# CC2756 register map
File version: 1.0
CPU: CM4 r0p4, little endian, no MPU, no FPU, VTOR, 3 interrupt priority bits
Registers are 32-bit, read-write, reset 0x0 unless marked. A register's access mark holds for its fields unless they carry their own. Offsets are from the block's base; [hi:lo] are bit positions; lines under a group give offsets from that group; {n}, {i} and the like mark numbered series; 'fields as' and 'values as' point back to an identical list.

## FLASH
Base 0x40021000
0x20 IIDX ro — Interrupt Index Register: The IIDX register provides the highest priority enabled interrupt index. PSD compliant register. Note that it is not recommended to use this register if the system clock is running at a slower clock frequency than the flash wrapper clock. If this is the case, then reading this register may fail to update the RIS register correctly. The MIS register should be read directly, and a write to ICLR should be used to clear interrupts when this clock relationship is present.
  [0] STAT — Indicates which interrupt has fired. 0x0 means no event pending. The priority order is fixed. On each read, only one interrupt is indicated. On a read, the current interrupt (highest priority) is automatically cleared by the hardware and the corresponding interrupt flags in the RIS and MIS are cleared as well. After a read from the CPU (not from the debug interface), the register must be updated with the next highest priority interrupt.
    1=DONE (DONE Interrupt Pending); 0=NO_INTR (No Interrupt Pending)
0x28 IMASK — Interrupt Mask Register: The IMASK register holds the current interrupt mask settings. Masked interrupts are read in the MIS register. PSD compliant register.
  [0] DONE — Interrupt mask for DONE: 0: Interrupt is disabled in MIS register 1: Interrupt is enabled in MIS register
    1=ENABLED (Interrupt will request an interrupt service routine and corresponding bit in IPSTANDARD.MIS will be set); 0=DISABLED (Interrupt is masked out)
0x30 RIS ro — Raw Interrupt Status Register: The RIS register reflects all pending interrupts, regardless of masking. The RIS register allows the user to implement a poll scheme. A flag set in this register can be cleared by writing a 1 to the ICLR register bit even if the corresponding IMASK bit is not enabled. A flag can be set by software by writing a 1 to the ISET register. Reading the IIDX register will also clear the corresponding bit in RIS. PSD compliant register.
  [0] DONE — Flash wrapper operation completed. This interrupt bit is set by firmware or the corresponding bit in the ISET register. It is cleared by the corresponding bit in in the ICLR register or reading the IIDX register when this interrupt is the highest priority.
    1=SET (Interrupt occurred); 0=CLR (Interrupt did not occur)
0x38 MIS ro — Masked Interrupt Status Register: The MIS register is a bit-wise AND of the contents of the IMASK and RIS registers. This is kept mainly for ARM compatibility, and has limited use since the highest priority interrupt index is returned via the IIDX register. PSD compliant register.
  [0] DONE — Flash wrapper operation completed. This masked interrupt bit reflects the bitwise AND of the corresponding RIS and IMASK bits.
    1=SET (Masked interrupt occurred); 0=CLR (Masked interrupt did not occur)
0x40 ISET wo — Interrupt Set Register: The ISET register allows software to write a 1 to set corresponding interrupt. Safety: This meets a safety requirement to allow software diagnostics to trigger interrupts. PSD compliant register.
  [0] DONE — 0: No effect 1: Set the DONE interrupt in the RIS register
    1=SET (Set IPSTANDARD.RIS bit); 0=NO_EFFECT (Writing a 0 has no effect)
0x48 ICLR wo — Interrupt Clear Register. The ICLR register allows allows software to write a 1 to clear corresponding interrupt. PSD compliant register.
  [0] DONE — 0: No effect 1: Clear the DONE interrupt in the RIS register
    1=CLR (Clear IPSTANDARD.RIS bit); 0=NO_EFFECT (Writing a 0 has no effect)
0xE0 EVT_MODE ro reset 0x1 — Event mode register. It is used to select whether each line is disabled, in software mode (software clears the RIS) or in hardware mode (hardware clears the RIS).
  [1:0] INT0_CFG — Event line mode select for peripheral event
    2=HARDWARE (The interrupt or event line is in hardware mode. Hardware should clear the RIS.); 1=SOFTWARE (The interrupt or event line is in software mode. Software must clear the RIS.); 0=DISABLE (The interrupt or event line is disabled.)
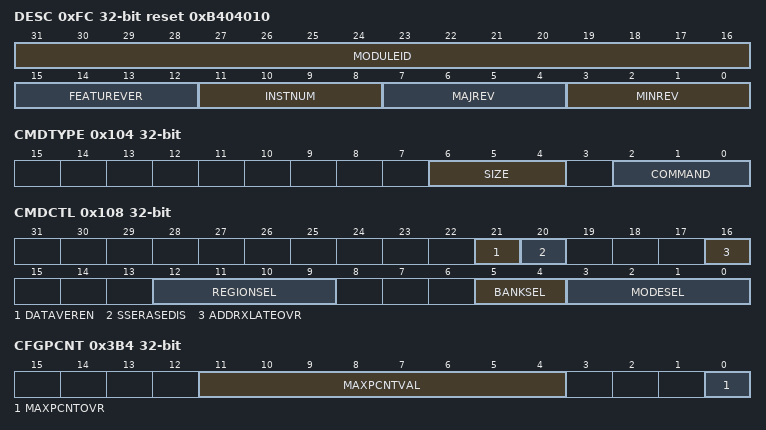
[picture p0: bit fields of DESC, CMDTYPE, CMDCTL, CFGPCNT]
0xFC DESC ro reset 0xB404010 — Hardware Version Description Register: This register identifies the flash wrapper hardware version and feature set used.
  [31:16] MODULEID
    0xFFFF=MAXIMUM (Highest possible value); 0=MINIMUM (Smallest value)
  [15:12] FEATUREVER — Feature set
    15=MAXIMUM (Maximum Value); 0=MINIMUM (Minimum Value)
  [11:8] INSTNUM — Instance number
    15=MAXIMUM (Highest possible value); 0=MINIMUM (Smallest value)
  [7:4] MAJREV — Major Revision
    values as INSTNUM
  [3:0] MINREV — Minor Revision
    values as INSTNUM
0x100 CMDEXEC — Command Execute Register: Initiates execution of the command specified in the CMDTYPE register. This register is blocked for writes after being written to 1 and prior to STATCMD.DONE being set by the flash wrapper hardware. flash wrapper hardware clears this register after the processing of the command has completed.
  [0] VAL — Command Execute value Initiates execution of the command specified in the CMDTYPE register.
    1=EXECUTE (Command will execute or is executing in flash wrapper); 0=NOEXECUTE (Command will not execute or is not executing in flash wrapper)
0x104 CMDTYPE — Command Type Register This register specifies the type of command to be executed by the flash wrapper hardware. This register is blocked for writes after CMDEXEC is written to a 1 and prior to STATCMD.DONE being set by the hardware to indicate that command execution has completed.
  [6:4] SIZE — Command size
    5=BANK (Operate on an entire flash bank); 4=SECTOR (Operate on a flash sector); 3=EIGHTWORD (Operate on 8 flash words); 2=FOURWORD (Operate on 4 flash words); 1=TWOWORD (Operate on 2 flash words); 0=ONEWORD (Operate on 1 flash word)
  [2:0] COMMAND — Command type
    6=BLANKVERIFY (Blank Verify - Check whether a flash word is in the erased state. This command may only be used with CMDTYPE.SIZE = ONEWORD); 5=CLEARSTATUS (Clear Status - Clear status bits in FW_SMSTAT only.); 4=MODECHANGE (Mode Change - Perform a mode change only, no other operation.); 3=READVERIFY (Read Verify - Perform a standalone read verify operation.); 2=ERASE; 1=PROGRAM; 0=NOOP (No Operation)
0x108 CMDCTL — Command Control Register This register configures specific capabilities of the state machine for related to the execution of a command. This register is blocked for writes after CMDEXEC is written to a 1 and prior to STATCMD.DONE being set by the hardware to indicate that command execution has completed.
  [21] DATAVEREN — Enable invalid data verify. This checks for 0-$gt;1 transitions in the memory when a program operation is initiated. If such a transition is found, the program will fail with an error without doing any programming.
    1=ENABLE; 0=DISABLE
  [20] SSERASEDIS — Disable Stair-Step Erase. If set, the default VHV trim voltage setting will be used for all erase pulses. By default, this bit is reset, meaning that the VHV voltage will be stepped during successive erase pulses. The step count, step voltage, begin and end voltages are all hard-wired.
    1=DISABLE; 0=ENABLE
  [16] ADDRXLATEOVR — Override hardware address translation of address in CMDADDR from a system address to a bank address and bank ID. Use data written to CMDADDR directly as the bank address. Use the value written to CMDCTL.BANKSEL directly as the bank ID. Use the value written to CMDCTL.REGIONSEL directly as the region ID.
    1=OVERRIDE; 0=NOOVERRIDE (Do not override)
  [12:9] REGIONSEL — Bank Region A specific region ID can be written to this field to indicate to which region an operation should be applied if CMDCTL.ADDRXLATEOVR is set.
    8=ENGR (Engr Region); 4=TRIM (Trim Region); 2=NONMAIN (Non-Main Region); 1=MAIN (Main Region)
  [5:4] BANKSEL — Bank Select A specific Bank ID can be written to this field to indicate to which bank an operation should be applied if CMDCTL.ADDRXLATEOVR is set.
    16=BANK4; 8=BANK3; 4=BANK2; 2=BANK1; 1=BANK0
  [3:0] MODESEL — Mode This field is only used for the Mode Change command type. Otherwise, bank and pump modes are set automaticlly via the NW hardware.
    15=ERASEBNK (Erase Bank); 14=PGMMW (Program Multiple Word); 12=ERASESECT (Erase Sector); 11=ERASEVER (Erase Verify Mode); 10=PGMSW (Program Single Word); 9=PGMVER (Program Verify Mode); 7=RDMARG1B (Read Margin 1B Mode); 6=RDMARG0B (Read Margin 0B Mode); 4=RDMARG1 (Read Margin 1 Mode); 2=RDMARG0 (Read Margin 0 Mode); 0=READ (Read Mode)
0x120 CMDADDR — Command Address Register: This register forms the target address of a command. The use cases are as follows: 1) For single-word program, this address indicates the flash bank word to be programmed. 2) For multi-word program, this address indicates the first flash bank address for the program. The address will be incremented for further words. 3) For sector erase, this address indicates the sector to be erased. 4) For bank erase, the address indicates the bank to be erased. 5) For read verify, the address indications follow program/erase listed above. Note the address written to this register will be submitted for translation to the flash wrapper address translation interface, and the translated address will be used to access the bank. However, if the CMDCTL.ADDRXLATEOVR bit is set, then the address written to this register will be used directly as the bank address. This register is blocked for writes after a 1 is written to the CMDEXEC register and prior to STATCMD.DONE being set by the flash wrapper hardware.
  [31:0] VAL — Address value
    0xFFFFFFFF=MAXIMUM (Maximum value of VAL); 0=MINIMUM (Minimum value of VAL)
0x124 CMDBYTEN — Command Program Byte Enable Register: This register forms a per-byte enable for programming data. For data bytes to be programmed, a 1 must be written to the corresponding bit in this register. Normally, all bits are written to 1, allowing program of full flash words. However, leaving some bits 0 allows programming of 8-bit, 16-bit, 32-bit or 64-bit portions of a flash word. In addtion, the read verify command will ignore data bytes read from the flash in its comparison if the corresponding CMDBYTEN bit is 0. ECC data bytes are protected by the 1-2 MSB bits in this register, depending on the presence of ECC and the flash word data width. This register is blocked for writes after a 1 is written to the CMDEXEC register and prior to STATCMD.DONE being set by the flash wrapper hardware. This register is written to all 0 after the completion of all flash wrapper commands.
  [15:0] VAL — Command Byte Enable value. A 1-bit per flash word byte value is placed in this register.
    0x3FFFF=MAXIMUM (Maximum value of VAL); 0=MINIMUM (Minimum value of VAL)
0x130 CMDDATA0 reset 0xFFFFFFFF — Command Data Register 0 This register forms the data for a command. For DATAWIDTH == 128: This register represents bits 31:0 of flash word data register 0. For DATAWIDTH == 64: This register represents bits 31:0 of flash word data register 0. This register is blocked for writes after a 1 is written to the CMDEXEC register and prior to STATCMD.DONE being set by the flash wrapper hardware. This register is used to aggregate masking for bits that do not require additional program pulses during program operations, and will be written to all 1 after the completion of all flash wrapper commands. Use cases for the CMDDATA* registers are as follows: 1) Program - These registers contain the data to be programmed. 2) Erase - These registers are not used. 3) Read Verify - These registers contain data to be verified.
  [31:0] VAL — A 32-bit data value is placed in this field.
    values as CMDADDR.VAL
0x134 CMDDATA1 reset 0xFFFFFFFF — Command Data Register 1 This register forms the data for a command. For DATAWIDTH == 128: This register represents bits 63:32 of flash word data register 0. For DATAWIDTH == 64: This register represents bits 63:32 of flash word data register 0. This register is blocked for writes after a 1 is written to the CMDEXEC register and prior to CMDSTAT.DONE being set by the flash wrapper hardware. This register is used to aggregate masking for bits that do not require additional program pulses during program operations, and will be written to all 1 after the completion of all flash wrapper commands. Use cases for the CMDDATA* registers are as follows: 1) Program - These registers contain the data to be programmed. 2) Erase - These registers are not used. 3) Read Verify - These registers contain data to be verified.
  fields as CMDDATA0
0x138 CMDDATA2 reset 0xFFFFFFFF — Command Data Register 2 This register forms the data for a command. For DATAWIDTH == 128: This register represents bits 95:64 of flash word data register 0. For DATAWIDTH == 64: This register represents bits 31:0 of flash word data register 1. This register is blocked for writes after a 1 is written to the CMDEXEC register and prior to STATCMD.DONE being set by the flash wrapper hardware. This register is used to aggregate masking for bits that do not require additional program pulses during program operations, and will be written to all 1 after the completion of all flash wrapper commands. Use cases for the CMDDATA* registers are as follows: 1) Program - These registers contain the data to be programmed. 2) Erase - These registers are not used. 3) Read Verify - These registers contain data to be verified.
  fields as CMDDATA0
0x13C CMDDATA3 reset 0xFFFFFFFF — Command Data Register 3 This register forms the data for a command. For DATAWIDTH == 128: This register represents bits 127:96 of flash word data register 0. For DATAWIDTH == 64: This register represents bits 63:32 of flash word data register 1. This register is blocked for writes after a 1 is written to the CMDEXEC register and prior to STATCMD.DONE being set by the flash wrapper hardware. This register is used to aggregate masking for bits that do not require additional program pulses during program operations, and will be written to all 1 after the completion of all flash wrapper commands. Use cases for the CMDDATA* registers are as follows: 1) Program - These registers contain the data to be programmed. 2) Erase - These registers are not used. 3) Read Verify - These registers contain data to be verified.
  fields as CMDDATA0
0x1D0 CMDWEPROTA reset 0xFFFFFFFF — Command WriteErase Protect A Register This register allows the first 32 sectors of the main region to be protected from program or erase, with 1 bit protecting each sector. If the main region size is smaller than 32 sectors, then this register provides protection for the whole region. This register is blocked for writes after a 1 is written to the CMDEXEC register and prior to STATCMD.DONE being set by the flash wrapper hardware. In addition, this register is used to aggregate masking for sectors that do not require additional erase pulses during bank erase operations, and will be written to all 1 after the completion of all flash wrapper commands.
  [31:0] VAL — Each bit protects 1 sector. bit [0]: When 1, sector 0 of the flash memory will be protected from program and erase. bit [1]: When 1, sector 1 of the flash memory will be protected from program and erase. : : bit [31]: When 1, sector 31 of the flash memory will be protected from program and erase.
    values as CMDADDR.VAL
0x1D4 CMDWEPROTB reset 0xFFFFFFFF — Command WriteErase Protect B Register This register allows main region sectors to be protected from program and erase. Each bit corresponds to a group of 8 sectors. There are 3 cases for how these protect bits are applied: 1. Single-bank system: In the case where only a single flash bank is present, the first 32 sectors are protected via the CMDWEPROTA register. Thus, the protection give by the bits in CMDWEPROTB begin with sector 32. 2. Multi-bank system, Bank 0: When multiple flash banks are present, the first 32 sectors of bank 0 are protected via the CMDWEPROTA register. Thus, only bits 4 and above of CMDWEPROTB would be applicable to bank 0. The protection of bit 4 and above would begin at sector 32. Bits 3:0 of WEPROTB are ignored for bank 0. 3. Multi-bank system, Banks 1-N: For banks other than bank 0 in a multi-bank system, CMDWEPROTA has no effect, so the bits in CMDWEPROTB will protect these banks starting from sector 0. This register is blocked for writes after a 1 is written to the CMDEXEC register and prior to STATCMD.DONE being set by the flash wrapper hardware. In addition, this register is used to aggregate masking for sectors that do not require additional erase pulses during bank erase operations, and will be written to all 1 after the completion of all flash wrapper commands.
  [31:0] VAL — Each bit protects a group of 8 sectors. When a bit is 1, the associated 8 sectors in the flash will be protected from program and erase. A maximum of 256 sectors can be protected with this register.
    values as CMDADDR.VAL
0x210 CMDWEPROTNM reset 0x3 — Command WriteErase Protect Non-Main Register This register allows non-main region region sectors to be protected from program and erase. Each bit corresponds to 1 sector. This register is blocked for writes after a 1 is written to the CMDEXEC register and prior to STATCMD.DONE being set by the flash wrapper hardware. In addition, this register is used to aggregate masking for sectors that do not require additional erase pulses during bank erase operations, and will be written to all 1 after the completion of all flash wrapper commands.
  [1:0] VAL — Each bit protects 1 sector. bit [0]: When 1, sector 0 of the non-main region will be protected from program and erase. bit [1]: When 1, sector 1 of the non-main region will be protected from program and erase. : : bit [31]: When 1, sector 31 of the non-main will be protected from program and erase.
    values as CMDADDR.VAL
0x214 CMDWEPROTTR reset 0x1 — Command WriteErase Protect Trim Register This register allows trim region sectors to be protected from program and erase. Each bit corresponds to 1 sector. This register is blocked for writes after a 1 is written to the CMDEXEC register and prior to STATCMD.DONE being set by the flash wrapper hardware. In addition, this register is used to aggregate masking for sectors that do not require additional erase pulses during bank erase operations, and will be written to all 1 after the completion of all flash wrapper commands.
  [0] VAL — Each bit protects 1 sector. bit [0]: When 1, sector 0 of the engr region will be protected from program and erase. bit [1]: When 1, sector 1 of the engr region will be protected from program and erase. : : bit [31]: When 1, sector 31 of the engr region will be protected from program and erase.
    values as CMDADDR.VAL
0x218 CMDWEPROTEN reset 0x1 — Command WriteErase Protect Engr Register This register allows engr region sectors to be protected from program and erase. Each bit corresponds to 1 sector. This register is blocked for writes after a 1 is written to the CMDEXEC register and prior to STATCMD.DONE being set by the flash wrapper hardware. In addition, this register is used to aggregate masking for sectors that do not require additional erase pulses during bank erase operations, and will be written to all 1 after the completion of all flash wrapper commands.
  fields as CMDWEPROTTR
0x3B0 CFGCMD reset 0x2 — Command Configuration Register This register configures specific capabilities of the state machine for related to the execution of a command. This register is blocked for writes after CMDEXEC is written to a 1 and prior to STATCMD.DONE being set by the hardware to indicate that command execution has completed.
  [3:0] WAITSTATE — Wait State setting for program verify, erase verify and read verify
    15=MAXIMUM (Maximum value); 0=MINIMUM (Minimum value)
0x3B4 CFGPCNT — Pulse Counter Configuration Register This register allows further configuration of maximum pulse counts for program and erase operations. This register is blocked for writes after a 1 is written to the CMDEXEC register and prior to STATCMD.DONE being set by the flash wrapper hardware.
  [11:4] MAXPCNTVAL — Override maximum pulse counter with this value. If MAXPCNTOVR = 0, then this field is ignored. If MAXPCNTOVR = 1 and MAXERSPCNTOVR = 0, then this value will be used to override the max pulse count for both program and erase. Full max value will be {4'h0, MAXPCNTVAL} . If MAXPCNTOVR = 1 and MAXERSPCNTOVR = 1, then this value will be used to override the max pulse count for program only. Full max value will be {4'h0, MAXPCNTVAL}.
    255=MAXIMUM (Maximum value); 0=MINIMUM (Minimum value)
  [0] MAXPCNTOVR — Override hard-wired maximum pulse count. If MAXERSPCNTOVR is not set, then setting this value alone will override the max pulse count for both program and erase. If MAXERSPCNTOVR is set, then this bit will only control the max pulse count setting for program. By default, this bit is 0, and a hard-wired max pulse count is used.
    1=OVERRIDE (Use value from MAXPCNTVAL field as maximum puse count); 0=DEFAULT (Use hard-wired (default) value for maximum pulse count)
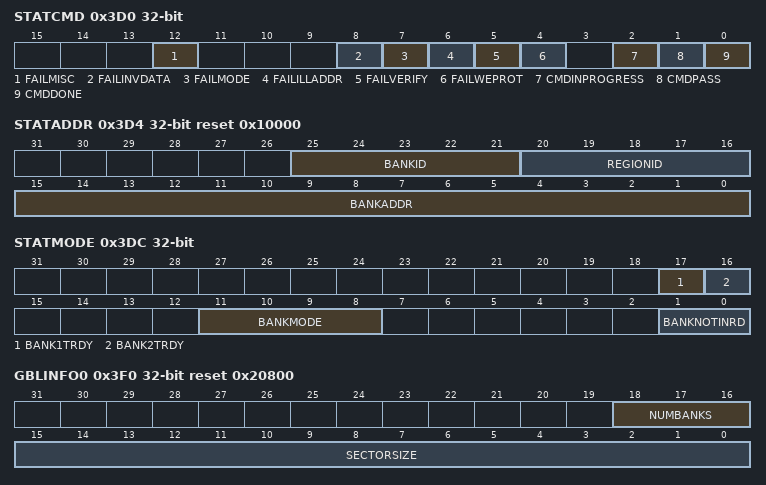
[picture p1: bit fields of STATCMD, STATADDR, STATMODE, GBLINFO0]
0x3D0 STATCMD ro — Command Status Register This register contains status regarding completion and errors of command execution.
  [12] FAILMISC — Command failed due to error other than write/erase protect violation or verify error. This is an extra bit in case a new failure mechanism is added which requires a status bit.
    1=STATFAIL (Fail); 0=STATNOFAIL (No Fail)
  [8] FAILINVDATA — Program command failed because an attempt was made to program a stored 0 value to a 1.
    1=STATFAIL (Fail); 0=STATNOFAIL (No Fail)
  [7] FAILMODE — Command failed because a bank has been set to a mode other than READ. Program and Erase commands cannot be initiated unless all banks are in READ mode.
    1=STATFAIL (Fail); 0=STATNOFAIL (No Fail)
  [6] FAILILLADDR — Command failed due to the use of an illegal address
    1=STATFAIL (Fail); 0=STATNOFAIL (No Fail)
  [5] FAILVERIFY — Command failed due to verify error
    1=STATFAIL (Fail); 0=STATNOFAIL (No Fail)
  [4] FAILWEPROT — Command failed due to Write/Erase Protect Sector Violation
    1=STATFAIL (Fail); 0=STATNOFAIL (No Fail)
  [2] CMDINPROGRESS — Command In Progress
    1=STATINPROGRESS (In Progress); 0=STATCOMPLETE (Complete)
  [1] CMDPASS — Command Pass - valid when CMD_DONE field is 1
    1=STATPASS (Pass); 0=STATFAIL (Fail)
  [0] CMDDONE — Command Done
    1=STATDONE (Done); 0=STATNOTDONE (Not Done)
0x3D4 STATADDR ro reset 0x10000 — Current Address Counter Value Read only register giving read access to the state machine current address. A bank id, region id and address are stored in this register and are incremented as necessary during execution of a command.
  [25:21] BANKID — Current Bank ID A bank indicator is stored in this register which represents the current bank on which the state machine is operating. There is 1 bit per bank.
    16=BANK4; 8=BANK3; 4=BANK2; 2=BANK1; 1=BANK0
  [20:16] REGIONID — Current Region ID A region indicator is stored in this register which represents the current flash region on which the state machine is operating.
    values as CMDCTL.REGIONSEL
  [15:0] BANKADDR — Current Bank Address A bank offset address is stored in this register.
    0xFFFF=MAXIMUM (Maximum value); 0=MINIMUM (Minimum value)
0x3D8 STATPCNT ro — Current Pulse Count Register: Read only register giving read access to the state machine current pulse count value for program/erase operations.
  [11:0] PULSECNT — Current Pulse Counter Value
    0xFFF=MAXIMUM (Maximum value); 0=MINIMUM (Minimum value)
0x3DC STATMODE ro — Mode Status Register Indicates any banks which not in READ mode, and it indicates the mode which the bank(s) are in.
  [17] BANK1TRDY — Bank 1T Ready. Bank(s) are ready for 1T access. This is accomplished when the bank and pump have been trimmed.
    1=TRUE (Ready); 0=FALSE (Not ready)
  [16] BANK2TRDY — Bank 2T Ready. Bank(s) are ready for 2T access. This is accomplished when the pump has fully driven power rails to the bank(s).
    1=TRUE (Ready); 0=FALSE (Not ready)
  [11:8] BANKMODE — Indicates mode of bank(s) that are not in READ mode
    values as CMDCTL.MODESEL
  [1:0] BANKNOTINRD — Bank not in read mode. Indicates which banks are not in READ mode. There is 1 bit per bank.
    16=BANK4; 8=BANK3; 4=BANK2; 2=BANK1; 1=BANK0
0x3F0 GBLINFO0 ro reset 0x20800 — Global Info 0 Register Read only register detailing information about sector size and number of banks present.
  [18:16] NUMBANKS — Number of banks instantiated Minimum: 1 Maximum: 5
    5=MAXIMUM (Maximum value); 1=MINIMUM (Minimum value)
  [15:0] SECTORSIZE — Sector size in bytes
    0x800=TWOKB (Sector size is TWOKB); 0x400=ONEKB (Sector size is ONEKB)
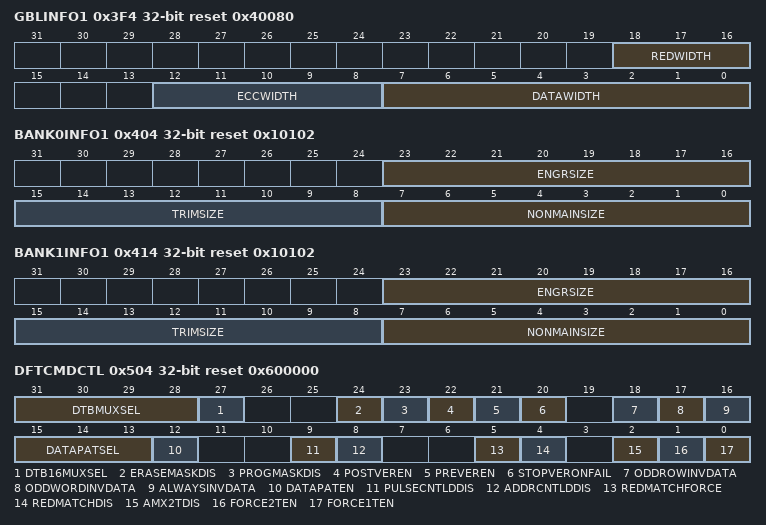
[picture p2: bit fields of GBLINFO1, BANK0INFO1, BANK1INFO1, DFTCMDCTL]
0x3F4 GBLINFO1 ro reset 0x40080 — Global Info 1 Register Read only register detailing information about data, ecc and redundant data widths in bits.
  [18:16] REDWIDTH — Redundant data width in bits
    4=W4BIT (Redundant data width is 4 bits); 2=W2BIT (Redundant data width is 2 bits); 0=W0BIT (Redundant data width is 0. Redundancy/Repair not present.)
  [12:8] ECCWIDTH — ECC data width in bits
    16=W16BIT (ECC data width is 16 bits); 8=W8BIT (ECC data width is 8 bits); 0=W0BIT (ECC data width is 0. ECC not used.)
  [7:0] DATAWIDTH — Data width in bits
    128=W128BIT (Data width is 128 bits); 64=W64BIT (Data width is 64 bits)
0x3F8 GBLINFO2 ro reset 0x1 — Global Info 2 Register Read only register detailing information about the number of data registers present.
  [3:0] DATAREGISTERS — Number of data registers present.
    8=MAXIMUM (Maximum value of DATAREGISTERS); 1=MINIMUM (Minimum value of DATAREGISTERS)
0x400 BANK0INFO0 ro reset 0x100 — Bank Info 0 Register for bank 0. Read only register detailing information about Main region size in the bank.
  [11:0] MAINSIZE — Main region size in sectors Minimum: 0x8 (8) Maximum: 0x200 (512)
    0x200=MAXSECTORS (Maximum value of MAINSIZE); 8=MINSECTORS (Minimum value of MAINSIZE)
0x404 BANK0INFO1 ro reset 0x10102 — Bank Info1 Register for bank 0. Read only register detailing information about Non-Main, Trim, and Engr region sizes in the bank.
  [23:16] ENGRSIZE — Engr region size in sectors Minimum: 0x0 (0) Maximum: 0x10 (16)
    32=MAXSECTORS (Maximum value of ENGRSIZE); 0=MINSECTORS (Minimum value of ENGRSIZE)
  [15:8] TRIMSIZE — Trim region size in sectors Minimum: 0x0 (0) Maximum: 0x10 (16)
    32=MAXSECTORS (Maximum value of TRIMSIZE); 0=MINSECTORS (Minimum value of TRIMSIZE)
  [7:0] NONMAINSIZE — Non-main region size in sectors Minimum: 0x0 (0) Maximum: 0x10 (16)
    32=MAXSECTORS (Maximum value of NONMAINSIZE); 0=MINSECTORS (Minimum value of NONMAINSIZE)
0x410 BANK1INFO0 ro reset 0x100 — Bank Info 0 Register for bank 1. Read only register detailing information about Main region size in the bank.
  fields as BANK0INFO0
0x414 BANK1INFO1 ro reset 0x10102 — Bank Info1 Register for bank 1. Read only register detailing information about Non-Main, Trim, and Engr region sizes in the bank.
  [23:16] ENGRSIZE — Engr region size in sectors Minimum: 0x0 (0) Maximum: 0x10 (16)
    values as BANK0INFO1.ENGRSIZE
  [15:8] TRIMSIZE — Trim region size in sectors
    values as BANK0INFO1.TRIMSIZE
  [7:0] NONMAINSIZE — Non-main region size in sectors
    values as BANK0INFO1.NONMAINSIZE
0x500 DFTEN — DFT Enable Register Allows control of flash wrapper test features. When set, DFT* registers in this aperture open for write access. When cleared, DFT* registers are read-only. This register is blocked for writes after a 1 is written to the CMDEXEC register and prior to STATCMD.DONE being set by the flash wrapper hardware.
  [0] ENABLE — Enable Test Features
    1=ENABLED (Command); 0=DISABLED (Command)
0x504 DFTCMDCTL reset 0x600000 — DFT Command Control Register This register configures specific capabilities for test. This register is only writable when DFTEN.ENABLE is set. This register is blocked for writes after a 1 is written to the CMDEXEC register and prior to STATCMD.DONE being set by the flash wrapper hardware.
  [31:28] DTBMUXSEL — DTB Mux Select This field will form the select for the primary DTB mux. This mux selects up to 16 sets of 32-bit fields of internal signals to be present to the 32-bit DTB output.
    15=MAXIMUM (Maximum value); 0=MINIMUM (Minimum value)
  [27] DTB16MUXSEL — DTB16 Mux Select This bit is valid when the flash wrapper DTB output bus width is less than 32 bits. Specifically, this bit is valid when the DTB width is 16 bits or less. When this is the case, then DTB16MUXSEL is used to select either the upper or lower 16-bit portion of the native 32-bit DTB bus. 8-bit portion of the 16-bit DTB value.
    1=UPPER16BITS (Select upper 16 bits of 32-bit DTB); 0=LOWER16BITS (Select lower 16 bits of 32-bit DTB)
  [24] ERASEMASKDIS — Disable use of erase mask for erase Bit masking will not be used during erase verify. If any sectors fail the verify either before (prever) or after (postver) the operation, then all specified flash sectors will receive subsequent erase pulse.
    1=DISABLE; 0=ENABLE
  [23] PROGMASKDIS — Disable use of program mask for programming. Bit masking will not be used during program verify. If any bits fail the verify either before (prever) or after (postver) the operation, then all specified flash entries will receive subsequent program pulse.
    1=DISABLE; 0=ENABLE
  [22] POSTVEREN — Enable verify after program or erase
    1=ENABLE; 0=DISABLE
  [21] PREVEREN — Enable verify before program or erase. For program, bits already programmed to the requested value will be masked. For erase, sectors already erased will be masked.
    1=ENABLE; 0=DISABLE
  [20] STOPVERONFAIL — Stop read verify on fail. If this bit is set, read verify will halt when the first verify fail is detected. If command is program or erase, another program or erase pulse will be executed. If command is read verify, comand will terminate.
    1=ENABLE; 0=DISABLE
  [18] ODDROWINVDATA — Invert data at odd row addresses for program or verify. The LSB of the row address is bit [4] of the bank address. This bit only applies when pattern data is used; i.e. the DATAPATEN bit is set. It will have no effect if CMDDATA is used.
    1=INVERT (Use inverted data); 0=TRUE (Use true data)
  [17] ODDWORDINVDATA — Invert data at odd bank addresses for program or verify. This bit only applies when pattern data is used; i.e. the DATAPATEN bit is set. It will have no effect if CMDDATA is used.
    1=INVERT (Use inverted data); 0=TRUE (Use true data)
  [16] ALWAYSINVDATA — Invert data always for program or verify. This bit only applies when pattern data is used; i.e. the DATAPATEN bit is set. It will have no effect if CMDDATA is used.
    1=INVERT (Use inverted data); 0=TRUE (Use true data)
  [15:13] DATAPATSEL — Select data pattern. Valid when DATAPATEN bit is set to 1. Overrides CMDDATA registers for program or verify.
    2=LOGCHKBRD (Set to logical checkerboard (0x01010101...)); 1=ALL1 (Set to all 1); 0=ALL0 (Set to all 0)
  [12] DATAPATEN — Enable data pattern. Data pattern select in DATAPATSEL field will override data from CMDDATA registers for use as program or verify data.
    1=ENABLE; 0=DISABLE
  [9] PULSECNTLDDIS — Override pulse counter enable. When set, the state machine pulse counter will not be loaded when a command is initiated.
    1=DISABLE; 0=ENABLE
  [8] ADDRCNTLDDIS — Override address counter enable. When set, the state machine address counter will not be loaded when a command is initiated.
    1=DISABLE; 0=ENABLE
  [5] REDMATCHFORCE — Force redundancy match. If set to 1, repair configuration encoded in the flash bank trim will be forced for every access.
    1=ENABLE; 0=DISABLE
  [4] REDMATCHDIS — Disable redundancy matching. Any repair configuration encoded into the bank trim bits is disabled.
    1=DISABLE; 0=ENABLE
  [2] AMX2TDIS — 2T address mux disable control. When set to 1 2T address shifting is disabled. This bit should only be enabled for reads. Indeterminate behavior will result if this bit is set during program/erase. Furthermore, only reads done via a READVERIFY command will be guaranteed to work properly. Reads via the FBAP port are not guaranteed to operate.
    1=DISABLE; 0=ENABLE
  [1] FORCE2TEN — Force 2T Enable - Force 2T access to regions that are designated as 1T. Regions designated as 2T will still be accessed as 2T.
    1=ENABLE; 0=DISABLE
  [0] FORCE1TEN — Force 1T Enable - Force 1T access to regions that are designated as 2T. Regions designated as 1T will still be accessed as 1T.
    1=ENABLE; 0=DISABLE
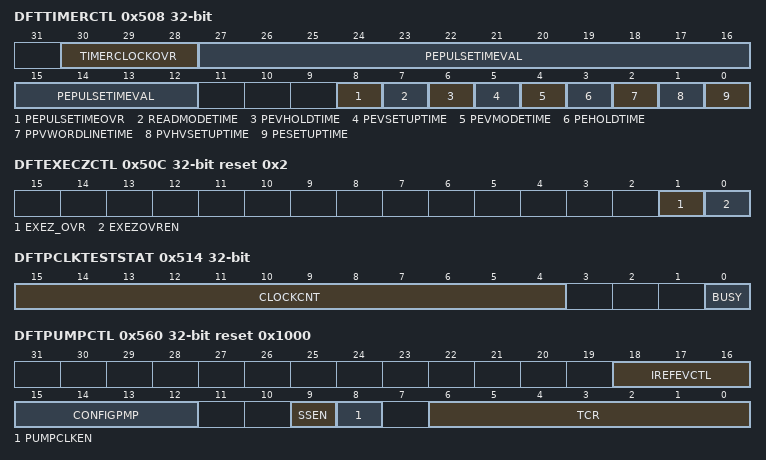
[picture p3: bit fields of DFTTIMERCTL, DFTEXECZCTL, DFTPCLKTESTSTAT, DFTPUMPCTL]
0x508 DFTTIMERCTL — DFT Timer Control Register This allows some configuration of timing values for various phases of flash operations for test. These time values are hard-coded for functional execution. This register is only writable when DFT.ENABLE is set. This register is blocked for writes after a 1 is written to the CMDEXEC register and prior to STATCMD.DONE being set by the flash wrapper hardware.
  [30:28] TIMERCLOCKOVR — Override Timer clock frequency using an ICG-based clock divide mechanism. To divide the timer clock, pulses can be skipped based on settings in this field. By default, this field is 0, which corresponds to no division on the timer clock.
    {v}=DIVIDEBY{v+1} (Divide timer clock by {v+1}) (v=1..7); 0=NODIVIDE (No divide on timer clock)
  [27:12] PEPULSETIMEVAL — Program/Erase Pulse Time Value If operation is a program, this value gets loaded into bits [15:0] of the timer when the PEPULSETIMEVALOVR field is set to 1. If operation is an erase, this value gets loaded into bits [19:4] of the timer when the PEPULSETIMEVALOVR field is set to 1.
    0xFFFF=MAXIMUM (Maximum value); 1=MINIMUM (Minimum value)
  [8] PEPULSETIMEOVR — Override Program/Erase Pulse Time If set, this will force the program or erase pulse time to be overridden with the value in the PEPULSETIMEVAL field. If not set, then a hard-coded value will be used for this pulse time.
    1=OVERRIDE (Use value from the PE_PULSE_TIME field for time value); 0=FUNCTIONAL (Use hard-wired (Functional) timer value)
  [7] READMODETIME — Read Mode Change Time
    1=TWOXFUNCTIONAL (Use 2x the hard-wired (functional) time value); 0=FUNCTIONAL (Use hard-wired (Functional) timer value)
  [6] PEVHOLDTIME — Program/Erase Verify Hold Time
    values as READMODETIME
  [5] PEVSETUPTIME — Program/Erase Verify Setup Time
    values as READMODETIME
  [4] PEVMODETIME — Program/Erase Verify Mode Change Time
    values as READMODETIME
  [3] PEHOLDTIME — Program/Erase Hold Time
    values as READMODETIME
  [2] PPVWORDLINETIME — Program and Program Verify Wordline Switching Time
    values as READMODETIME
  [1] PVHVSETUPTIME — Program VHV Setup Time
    values as READMODETIME
  [0] PESETUPTIME — Program/Erase Setup Time
    values as READMODETIME
0x50C DFTEXECZCTL reset 0x2 — DFT EXECUTEZ control register. This register allows direct control of the EXECUTEZ to bank and pump for test. This register is only writable when DFTEN.ENABLE is set. This register is blocked for writes after a 1 is written to the CMDEXEC register and prior to STATCMD.DONE being set by the flash wrapper hardware.
  [1] EXEZ_OVR — Override value to be applied to EXECUTEZ
    1=ONE (Set EXECUTEZ to 1); 0=ZERO (Set EXECUTEZ to 0)
  [0] EXEZOVREN — Enable override of EXECUTEZ Note that when this bit is set, the flash wrapper has control of the bank pins.
    1=ENABLE; 0=DISABLE
0x510 DFTPCLKTESTCTL — DFT Pump Clock Test Control Register. This register controls hardware features that allow the pump clock to be characterized for trim development. This register is only writable when DFTEN.ENABLE is set. This register is blocked for writes after a 1 is written to the CMDEXEC register and prior to STATCMD.DONE being set by the flash wrapper hardware.
  [0] ENABLE — Enable the state machine which sequences measurement of pump clock frequency.
    1=ENABLE; 0=DISABLE
0x514 DFTPCLKTESTSTAT ro — DFT Pump Clock Test Status Register. This register shows status reported by the hardware features that allow the pump clock to be characterized for trim development. This register is only writable when DFTEN.ENABLE is set.
  [15:4] CLOCKCNT — Indicates the core clock count captured during the pump clock measurement.
    0xFFF=MAXIMUM (Maximum count value); 0=MINIMUM (Minimum count value)
  [0] BUSY — Indicates that a pump clock measurement is in progress.
    1=INPROGRESS (Indicates test in progress); 0=COMPLETE (Indicates test complete)
0x540 DFTDATARED0 reset 0xF — DFT Redundancy Data Register 0 This register is used when testing the redundant columns in the flash. It acts as an extension of the CMDDATA* registers. The bits in this register correspond to flash data word register 0. In addition, this register is used to aggregate masking for bits that do not require additional program pulses during program operations. The original data written to this register will be lost during program command execution. Use cases for this register are as follows: 1) Program - Contains the data to be programmed. 2) Erase - Not used. 3) Read Verify - Contains data to be verified. This register is only writable when DFTEN.ENABLE is set. This register is blocked for writes after a 1 is written to the CMDEXEC register and prior to STATCMD.DONE being set by the flash wrapper hardware.
  [3:0] VAL — Data for redundant bits
0x560 DFTPUMPCTL reset 0x1000 — DFT Pump Control Register This allows some configuration of pump parameters during test. This register is only writable when DFTEN.ENABLE is set. This register is blocked for writes after a 1 is written to the CMDEXEC register and prior to STATCMD.DONE being set by the flash wrapper hardware.
  [18:16] IREFEVCTL — IREFEV control IREFVRD, REFTC, IREFCONST, IREFCCOR blocks in IREFEV
  [15:12] CONFIGPMP — Pump configuration control. LP, HP operation
  [9] SSEN — Dither control for oscillator Enumeration: 0: Disable Dither 1: Enable Dither
    1=ENABLE; 0=DISABLE
  [8] PUMPCLKEN — Allows direct control of the pump oscillator which is used to generate pumpclk. Normally, enable/disable of pumpclk is under flash wrapper state machine control. This bit allows system to enable the clock independently.
    1=ENABLE (Force pump clock oscillator to be enabled.); 0=HWCTL (Allow pump clock oscillator to be controlled by hardware.)
  [6:0] TCR — TCR test mode to be applied to the pump
    127=MAXIMUM (Maximum value); 0=MINIMUM (Minimum value)
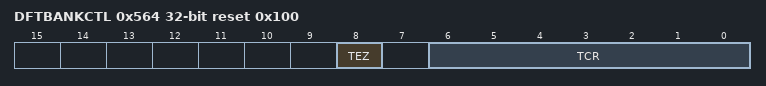
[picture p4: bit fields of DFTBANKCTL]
0x564 DFTBANKCTL reset 0x100 — DFT Bank Control Register This allows some configuration of bank parameters during test. This register is only writable when DFTEN.ENABLE is set. This register is blocked for writes after a 1 is written to the CMDEXEC register and prior to STATCMD.DONE being set by the flash wrapper hardware.
  [8] TEZ — When set, TEZ is asserted to the flash banks. Which banks get the asserted signal is determined by the BANKSELECT field in CMDCTL. 0x0 Do no assert TEZ 0x1 Assert TEZ
    1=NEGATE (Do not assert TEZ); 0=ASSERT (Assert TEZ)
  [6:0] TCR — TCR test mode to be applied to the bank
    127=MAXIMUM (Maximum value); 0=MINIMUM (Minimum value)
